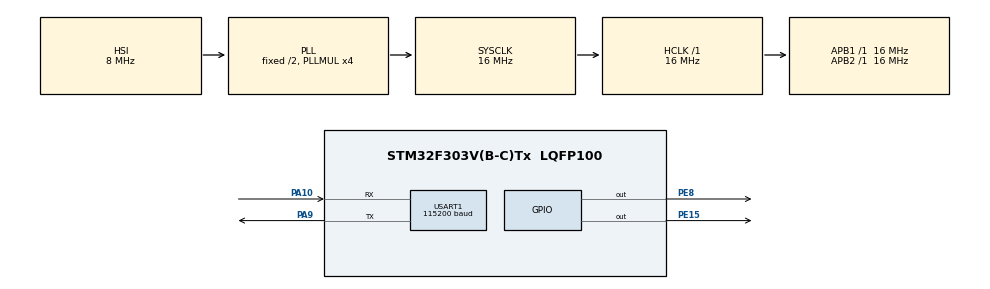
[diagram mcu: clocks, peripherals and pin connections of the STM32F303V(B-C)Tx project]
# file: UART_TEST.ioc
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Mcu.Family=STM32F3
Mcu.Name=STM32F303V(B-C)Tx
Mcu.Package=LQFP100
NVIC.PriorityGroup=NVIC_PRIORITYGROUP_4
NVIC.USART1_IRQn=true\:0\:0\:false\:false\:true\:true\:true
PA10.Mode=Asynchronous
PA10.Signal=USART1_RX
PA9.Mode=Asynchronous
PA9.Signal=USART1_TX
PE15.Signal=GPIO_Output
PE8.Signal=GPIO_Output
ProjectManager.HeapSize=0x200
ProjectManager.StackSize=0x400
ProjectManager.TargetToolchain=MDK-ARM V5.27
RCC.AHBFreq_Value=16000000
RCC.APB1Freq_Value=16000000
RCC.APB1TimFreq_Value=16000000
RCC.APB2Freq_Value=16000000
RCC.APB2TimFreq_Value=16000000
RCC.CortexFreq_Value=16000000
RCC.HCLKFreq_Value=16000000
RCC.HSE_VALUE=8000000
RCC.HSI_VALUE=8000000
RCC.LSE_VALUE=32768
RCC.PLLMUL=RCC_PLL_MUL4
RCC.SYSCLKFreq_VALUE=16000000
RCC.SYSCLKSourceVirtual=RCC_SYSCLKSOURCE_PLLCLK
RCC.USBFreq_Value=16000000
USART1.BaudRate=115200
USART1.VirtualMode-Asynchronous=VM_ASYNC
VP_CRC_VS_CRC.Mode=CRC_Activate
board=custom

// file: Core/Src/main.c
/* USER CODE BEGIN Header */
/**
  ******************************************************************************
  * @file           : main.c
  * @brief          : Main program body
  ******************************************************************************
  * @attention
  *
  * <h2><center>&copy; Copyright (c) 2023 STMicroelectronics.
  * All rights reserved.</center></h2>
  *
  * This software component is licensed by ST under BSD 3-Clause license,
  * the "License"; You may not use this file except in compliance with the
  * License. You may obtain a copy of the License at:
  *                        opensource.org/licenses/BSD-3-Clause
  *
  ******************************************************************************
  */
/* USER CODE END Header */
#include "main.h"

/* USER CODE BEGIN PD */
uint32_t ui32crc=0;
/* USER CODE END PD */

CRC_HandleTypeDef hcrc;

UART_HandleTypeDef huart1;

/* USER CODE BEGIN PV */
		uint8_t broj =0;
		uint8_t aui8Broj[100]={0};

/* USER CODE END PV */

void SystemClock_Config(void);
static void MX_GPIO_Init(void);
static void MX_USART1_UART_Init(void);
static void MX_CRC_Init(void);

/* USER CODE BEGIN 0 */

void HAL_UART_RxCpltCallback(UART_HandleTypeDef *huart){
		HAL_GPIO_WritePin(GPIOE,GPIO_PIN_15,GPIO_PIN_SET);
		ui32crc=HAL_CRC_Calculate(&hcrc ,(uint32_t*) aui8Broj,sizeof(aui8Broj)-4);
		uint32_t recCrc=*((uint32_t*) (&aui8Broj[96]));
		if(ui32crc == recCrc)
		{
			HAL_GPIO_WritePin(GPIOE,GPIO_PIN_8,GPIO_PIN_SET);
		}else{

			HAL_GPIO_WritePin(GPIOE,GPIO_PIN_8,GPIO_PIN_RESET);
		}

		 HAL_UART_Receive_IT(&huart1, aui8Broj, sizeof(aui8Broj));

}
/* USER CODE END 0 */

int main(void)
{
  /* USER CODE BEGIN 1 */

//uint8_t ui8counter=0;
//uint8_t ui8counter2=0;
  /* USER CODE END 1 */

  /* MCU Configuration--------------------------------------------------------*/

  /* Reset of all peripherals, Initializes the Flash interface and the Systick. */
  HAL_Init();

  /* Configure the system clock */
  SystemClock_Config();

  /* Initialize all configured peripherals */
  MX_GPIO_Init();
  MX_USART1_UART_Init();
  MX_CRC_Init();
  /* USER CODE BEGIN 2 */
   HAL_UART_Receive_IT(&huart1, aui8Broj, sizeof(aui8Broj));
  /* USER CODE END 2 */

  /* Infinite loop */
  while (1)
  {

  }
}

void SystemClock_Config(void)
{
  RCC_OscInitTypeDef RCC_OscInitStruct = {0};
  RCC_ClkInitTypeDef RCC_ClkInitStruct = {0};
  RCC_PeriphCLKInitTypeDef PeriphClkInit = {0};

  /** Initializes the RCC Oscillators according to the specified parameters
  * in the RCC_OscInitTypeDef structure.
  */
  RCC_OscInitStruct.OscillatorType = RCC_OSCILLATORTYPE_HSI;
  RCC_OscInitStruct.HSIState = RCC_HSI_ON;
  RCC_OscInitStruct.HSICalibrationValue = RCC_HSICALIBRATION_DEFAULT;
  RCC_OscInitStruct.PLL.PLLState = RCC_PLL_ON;
  RCC_OscInitStruct.PLL.PLLSource = RCC_PLLSOURCE_HSI;
  RCC_OscInitStruct.PLL.PLLMUL = RCC_PLL_MUL4;
  if (HAL_RCC_OscConfig(&RCC_OscInitStruct) != HAL_OK)
  {
    Error_Handler();
  }
  /** Initializes the CPU, AHB and APB buses clocks
  */
  RCC_ClkInitStruct.ClockType = RCC_CLOCKTYPE_HCLK|RCC_CLOCKTYPE_SYSCLK
                              |RCC_CLOCKTYPE_PCLK1|RCC_CLOCKTYPE_PCLK2;
  RCC_ClkInitStruct.SYSCLKSource = RCC_SYSCLKSOURCE_PLLCLK;
  RCC_ClkInitStruct.AHBCLKDivider = RCC_SYSCLK_DIV1;
  RCC_ClkInitStruct.APB1CLKDivider = RCC_HCLK_DIV1;
  RCC_ClkInitStruct.APB2CLKDivider = RCC_HCLK_DIV1;

  if (HAL_RCC_ClockConfig(&RCC_ClkInitStruct, FLASH_LATENCY_0) != HAL_OK)
  {
    Error_Handler();
  }
  PeriphClkInit.PeriphClockSelection = RCC_PERIPHCLK_USART1;
  PeriphClkInit.Usart1ClockSelection = RCC_USART1CLKSOURCE_PCLK2;
  if (HAL_RCCEx_PeriphCLKConfig(&PeriphClkInit) != HAL_OK)
  {
    Error_Handler();
  }
}

static void MX_CRC_Init(void)
{

  hcrc.Instance = CRC;
  hcrc.Init.DefaultPolynomialUse = DEFAULT_POLYNOMIAL_ENABLE;
  hcrc.Init.DefaultInitValueUse = DEFAULT_INIT_VALUE_ENABLE;
  hcrc.Init.InputDataInversionMode = CRC_INPUTDATA_INVERSION_NONE;
  hcrc.Init.OutputDataInversionMode = CRC_OUTPUTDATA_INVERSION_DISABLE;
  hcrc.InputDataFormat = CRC_INPUTDATA_FORMAT_BYTES;
  if (HAL_CRC_Init(&hcrc) != HAL_OK)
  {
    Error_Handler();
  }

}

static void MX_USART1_UART_Init(void)
{

  huart1.Instance = USART1;
  huart1.Init.BaudRate = 115200;
  huart1.Init.WordLength = UART_WORDLENGTH_8B;
  huart1.Init.StopBits = UART_STOPBITS_1;
  huart1.Init.Parity = UART_PARITY_NONE;
  huart1.Init.Mode = UART_MODE_TX_RX;
  huart1.Init.HwFlowCtl = UART_HWCONTROL_NONE;
  huart1.Init.OverSampling = UART_OVERSAMPLING_16;
  huart1.Init.OneBitSampling = UART_ONE_BIT_SAMPLE_DISABLE;
  huart1.AdvancedInit.AdvFeatureInit = UART_ADVFEATURE_NO_INIT;
  if (HAL_UART_Init(&huart1) != HAL_OK)
  {
    Error_Handler();
  }

}

static void MX_GPIO_Init(void)
{
  GPIO_InitTypeDef GPIO_InitStruct = {0};

  /* GPIO Ports Clock Enable */
  __HAL_RCC_GPIOE_CLK_ENABLE();
  __HAL_RCC_GPIOA_CLK_ENABLE();

  /*Configure GPIO pin Output Level */
  HAL_GPIO_WritePin(GPIOE, GPIO_PIN_8|GPIO_PIN_15, GPIO_PIN_RESET);

  /*Configure GPIO pins : PE8 PE15 */
  GPIO_InitStruct.Pin = GPIO_PIN_8|GPIO_PIN_15;
  GPIO_InitStruct.Mode = GPIO_MODE_OUTPUT_PP;
  GPIO_InitStruct.Pull = GPIO_NOPULL;
  GPIO_InitStruct.Speed = GPIO_SPEED_FREQ_LOW;
  HAL_GPIO_Init(GPIOE, &GPIO_InitStruct);

}

void Error_Handler(void)
{
  __disable_irq();
  while (1)
  {
  }
}

/************************ (C) COPYRIGHT STMicroelectronics *****END OF FILE****/
